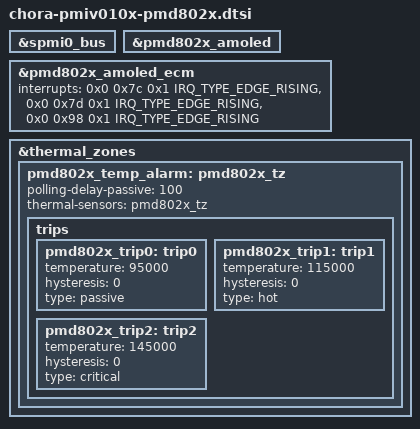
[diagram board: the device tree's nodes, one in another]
// SPDX-License-Identifier: BSD-3-Clause
/*
 * Copyright (c) Qualcomm Technologies, Inc. and/or its subsidiaries.
 */

#include <dt-bindings/iio/qcom,spmi-vadc.h>
#include <dt-bindings/iio/qcom,spmi-adc5-gen3-pmiv010x.h>

#include "chora-pmiv010x.dtsi"

&spmi0_bus {
	#include "pmd802x.dtsi"
};

/delete-node/ &pmiv010x_amoled;

&pmd802x_amoled {
	status = "ok";
};

&pmd802x_amoled_ecm {
	interrupts = <0x0 0x7c 0x1 IRQ_TYPE_EDGE_RISING>,
		     <0x0 0x7d 0x1 IRQ_TYPE_EDGE_RISING>,
		     <0x0 0x98 0x1 IRQ_TYPE_EDGE_RISING>;
};

&thermal_zones {
	pmd802x_temp_alarm: pmd802x_tz {
		polling-delay-passive = <100>;
		thermal-sensors = <&pmd802x_tz>;

		trips {
			pmd802x_trip0: trip0 {
				temperature = <95000>;
				hysteresis = <0>;
				type = "passive";
			};

			pmd802x_trip1: trip1 {
				temperature = <115000>;
				hysteresis = <0>;
				type = "hot";
			};

			pmd802x_trip2: trip2 {
				temperature = <145000>;
				hysteresis = <0>;
				type = "critical";
			};
		};
	};
};
